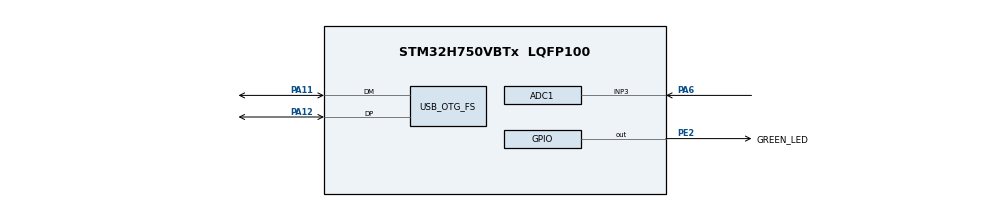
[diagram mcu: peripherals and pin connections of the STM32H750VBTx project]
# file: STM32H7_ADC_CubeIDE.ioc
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ADC1.Channel-0\#ChannelRegularConversion=ADC_CHANNEL_3
ADC1.ContinuousConvMode=DISABLE
ADC1.ConversionDataManagement=ADC_CONVERSIONDATA_DMA_CIRCULAR
ADC1.ExternalTrigConv=ADC_EXTERNALTRIG_T8_TRGO
ADC1.NbrOfConversion=1
ADC1.NbrOfConversionFlag=1
ADC1.OffsetNumber-0\#ChannelRegularConversion=ADC_OFFSET_NONE
ADC1.OffsetSignedSaturation-0\#ChannelRegularConversion=DISABLE
ADC1.OversamplingMode=ENABLE
ADC1.Rank-0\#ChannelRegularConversion=1
ADC1.Ratio=7
ADC1.RightBitShift=ADC_RIGHTBITSHIFT_3
ADC1.SamplingTime-0\#ChannelRegularConversion=ADC_SAMPLETIME_1CYCLE_5
ADC1.master=1
Dma.ADC1.0.Direction=DMA_PERIPH_TO_MEMORY
Dma.ADC1.0.EventEnable=DISABLE
Dma.ADC1.0.FIFOMode=DMA_FIFOMODE_DISABLE
Dma.ADC1.0.Instance=DMA1_Stream0
Dma.ADC1.0.MemDataAlignment=DMA_MDATAALIGN_HALFWORD
Dma.ADC1.0.MemInc=DMA_MINC_ENABLE
Dma.ADC1.0.Mode=DMA_CIRCULAR
Dma.ADC1.0.PeriphDataAlignment=DMA_PDATAALIGN_HALFWORD
Dma.ADC1.0.PeriphInc=DMA_PINC_DISABLE
Dma.ADC1.0.Polarity=HAL_DMAMUX_REQ_GEN_RISING
Dma.ADC1.0.Priority=DMA_PRIORITY_HIGH
Dma.ADC1.0.RequestNumber=1
Dma.ADC1.0.SignalID=NONE
Dma.ADC1.0.SyncEnable=DISABLE
Dma.ADC1.0.SyncPolarity=HAL_DMAMUX_SYNC_NO_EVENT
Dma.ADC1.0.SyncRequestNumber=1
Dma.ADC1.0.SyncSignalID=NONE
Dma.Request0=ADC1
Mcu.Family=STM32H7
Mcu.Name=STM32H750VBTx
Mcu.Package=LQFP100
NVIC.DMA1_Stream0_IRQn=true\:0\:0\:false\:false\:true\:false\:true\:true
NVIC.OTG_FS_IRQn=true\:0\:0\:false\:false\:true\:false\:true\:true
NVIC.PriorityGroup=NVIC_PRIORITYGROUP_4
PA11.Mode=Device_Only
PA11.Signal=USB_OTG_FS_DM
PA12.Mode=Device_Only
PA12.Signal=USB_OTG_FS_DP
PA13\ (JTMS/SWDIO).Mode=Serial_Wire
PA13\ (JTMS/SWDIO).Signal=DEBUG_JTMS-SWDIO
PA14\ (JTCK/SWCLK).Mode=Serial_Wire
PA14\ (JTCK/SWCLK).Signal=DEBUG_JTCK-SWCLK
PA6.Signal=ADCx_INP3
PC14-OSC32_IN\ (OSC32_IN).Mode=LSE-External-Oscillator
PC14-OSC32_IN\ (OSC32_IN).Signal=RCC_OSC32_IN
PC15-OSC32_OUT\ (OSC32_OUT).Mode=LSE-External-Oscillator
PC15-OSC32_OUT\ (OSC32_OUT).Signal=RCC_OSC32_OUT
PE2.GPIO_Label=GREEN_LED
PE2.Signal=GPIO_Output
PH0-OSC_IN\ (PH0).Mode=HSE-External-Oscillator
PH0-OSC_IN\ (PH0).Signal=RCC_OSC_IN
PH1-OSC_OUT\ (PH1).Mode=HSE-External-Oscillator
PH1-OSC_OUT\ (PH1).Signal=RCC_OSC_OUT
ProjectManager.HeapSize=0x400
ProjectManager.StackSize=0x800
ProjectManager.TargetToolchain=STM32CubeIDE
RCC.ADCFreq_Value=80000000
RCC.APB1Freq_Value=120000000
RCC.APB2Freq_Value=120000000
RCC.APB3Freq_Value=120000000
RCC.APB4Freq_Value=120000000
RCC.CortexFreq_Value=480000000
RCC.D1PPRE=RCC_APB3_DIV2
RCC.D2PPRE1=RCC_APB1_DIV2
RCC.D2PPRE2=RCC_APB2_DIV2
RCC.D3PPRE=RCC_APB4_DIV2
RCC.DIVM1=4
RCC.DIVM2=4
RCC.DIVN1=60
RCC.DIVN2=10
RCC.HCLKFreq_Value=240000000
RCC.HPRE=RCC_HCLK_DIV2
RCC.PLL2FRACN=0
RCC.PLL3FRACN=0
RCC.PLLFRACN=0
RCC.SYSCLKFreq_VALUE=480000000
RCC.SYSCLKSource=RCC_SYSCLKSOURCE_PLLCLK
RCC.USBCLockSelection=RCC_USBCLKSOURCE_HSI48
RCC.USBFreq_Value=48000000
SH.ADCx_INP3.0=ADC1_INP3,IN3-Single-Ended
TIM8.Period=2500-1
TIM8.Prescaler=2-1
TIM8.TIM_MasterOutputTrigger=TIM_TRGO_UPDATE
USB_DEVICE.CLASS_NAME_FS=CDC
USB_DEVICE.VirtualMode-CDC_FS=Cdc
USB_DEVICE.VirtualModeFS=Cdc_FS
USB_OTG_FS.VirtualMode=Device_Only
VP_MEMORYMAP_VS_MEMORYMAP.Mode=CurAppReg
VP_TIM8_VS_ClockSourceINT.Mode=Internal
VP_USB_DEVICE_VS_USB_DEVICE_CDC_FS.Mode=CDC_FS
board=custom

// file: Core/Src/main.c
/* USER CODE BEGIN Header */
/**
  ******************************************************************************
  * @file           : main.c
  * @brief          : Main program body
  ******************************************************************************
  * @attention
  *
  * Copyright (c) 2024 STMicroelectronics.
  * All rights reserved.
  *
  * This software is licensed under terms that can be found in the LICENSE file
  * in the root directory of this software component.
  * If no LICENSE file comes with this software, it is provided AS-IS.
  *
  ******************************************************************************
  */
/* USER CODE END Header */
#include "main.h"
#include "usb_device.h"

/* USER CODE BEGIN Includes */
#include "usbd_cdc_if.h"
/* USER CODE END Includes */

/* USER CODE BEGIN PD */
#define DMABUFLEN	2048
#define ADC_RAW_TO_VOLTAGE 0.00005035477f
/* USER CODE END PD */

ADC_HandleTypeDef hadc1;
DMA_HandleTypeDef hdma_adc1;

TIM_HandleTypeDef htim8;

/* USER CODE BEGIN PV */
volatile uint16_t dmaBuffer[DMABUFLEN];
volatile float potVoltage[DMABUFLEN];
volatile char msg[10];
/* USER CODE END PV */

void SystemClock_Config(void);
static void MX_GPIO_Init(void);
static void MX_DMA_Init(void);
static void MX_ADC1_Init(void);
static void MX_TIM8_Init(void);

/* USER CODE BEGIN 0 */

void HAL_ADC_ConvCpltCallback(ADC_HandleTypeDef *hadc){
	//HAL_GPIO_TogglePin(GREEN_LED_GPIO_Port, GREEN_LED_Pin);
	CDC_Transmit_FS((uint8_t*)&dmaBuffer[DMABUFLEN/2], DMABUFLEN);
//	HAL_ADC_Stop_DMA(&hadc1);
//	HAL_ADC_Start_DMA(&hadc1, (uint32_t*) dmaBuffer, DMABUFLEN);
}

void HAL_ADC_ConvHalfCpltCallback(ADC_HandleTypeDef *hadc){
	//HAL_GPIO_TogglePin(GREEN_LED_GPIO_Port, GREEN_LED_Pin);
	CDC_Transmit_FS((uint8_t*)&dmaBuffer[0], DMABUFLEN);
}
/* USER CODE END 0 */

int main(void)
{

  /* MCU Configuration--------------------------------------------------------*/

  /* Reset of all peripherals, Initializes the Flash interface and the Systick. */
  HAL_Init();

  /* Configure the system clock */
  SystemClock_Config();

  /* Initialize all configured peripherals */
  MX_GPIO_Init();
  MX_DMA_Init();
  MX_ADC1_Init();
  MX_TIM8_Init();
  MX_USB_DEVICE_Init();
  /* USER CODE BEGIN 2 */
  HAL_ADCEx_Calibration_Start(&hadc1, ADC_CALIB_OFFSET, ADC_SINGLE_ENDED);
  HAL_ADC_Start_DMA(&hadc1, (uint32_t*)dmaBuffer, DMABUFLEN);
  HAL_TIM_Base_Start(&htim8);
  /* USER CODE END 2 */

  /* Infinite loop */
  while (1)
  {

  }
}

void SystemClock_Config(void)
{
  RCC_OscInitTypeDef RCC_OscInitStruct = {0};
  RCC_ClkInitTypeDef RCC_ClkInitStruct = {0};

  /** Supply configuration update enable
  */
  HAL_PWREx_ConfigSupply(PWR_LDO_SUPPLY);

  /** Configure the main internal regulator output voltage
  */
  __HAL_PWR_VOLTAGESCALING_CONFIG(PWR_REGULATOR_VOLTAGE_SCALE1);

  while(!__HAL_PWR_GET_FLAG(PWR_FLAG_VOSRDY)) {}

  __HAL_RCC_SYSCFG_CLK_ENABLE();
  __HAL_PWR_VOLTAGESCALING_CONFIG(PWR_REGULATOR_VOLTAGE_SCALE0);

  while(!__HAL_PWR_GET_FLAG(PWR_FLAG_VOSRDY)) {}

  /** Initializes the RCC Oscillators according to the specified parameters
  * in the RCC_OscInitTypeDef structure.
  */
  RCC_OscInitStruct.OscillatorType = RCC_OSCILLATORTYPE_HSI48|RCC_OSCILLATORTYPE_HSI;
  RCC_OscInitStruct.HSIState = RCC_HSI_DIV1;
  RCC_OscInitStruct.HSICalibrationValue = RCC_HSICALIBRATION_DEFAULT;
  RCC_OscInitStruct.HSI48State = RCC_HSI48_ON;
  RCC_OscInitStruct.PLL.PLLState = RCC_PLL_ON;
  RCC_OscInitStruct.PLL.PLLSource = RCC_PLLSOURCE_HSI;
  RCC_OscInitStruct.PLL.PLLM = 4;
  RCC_OscInitStruct.PLL.PLLN = 60;
  RCC_OscInitStruct.PLL.PLLP = 2;
  RCC_OscInitStruct.PLL.PLLQ = 2;
  RCC_OscInitStruct.PLL.PLLR = 2;
  RCC_OscInitStruct.PLL.PLLRGE = RCC_PLL1VCIRANGE_3;
  RCC_OscInitStruct.PLL.PLLVCOSEL = RCC_PLL1VCOWIDE;
  RCC_OscInitStruct.PLL.PLLFRACN = 0;
  if (HAL_RCC_OscConfig(&RCC_OscInitStruct) != HAL_OK)
  {
    Error_Handler();
  }

  /** Initializes the CPU, AHB and APB buses clocks
  */
  RCC_ClkInitStruct.ClockType = RCC_CLOCKTYPE_HCLK|RCC_CLOCKTYPE_SYSCLK
                              |RCC_CLOCKTYPE_PCLK1|RCC_CLOCKTYPE_PCLK2
                              |RCC_CLOCKTYPE_D3PCLK1|RCC_CLOCKTYPE_D1PCLK1;
  RCC_ClkInitStruct.SYSCLKSource = RCC_SYSCLKSOURCE_PLLCLK;
  RCC_ClkInitStruct.SYSCLKDivider = RCC_SYSCLK_DIV1;
  RCC_ClkInitStruct.AHBCLKDivider = RCC_HCLK_DIV2;
  RCC_ClkInitStruct.APB3CLKDivider = RCC_APB3_DIV2;
  RCC_ClkInitStruct.APB1CLKDivider = RCC_APB1_DIV2;
  RCC_ClkInitStruct.APB2CLKDivider = RCC_APB2_DIV2;
  RCC_ClkInitStruct.APB4CLKDivider = RCC_APB4_DIV2;

  if (HAL_RCC_ClockConfig(&RCC_ClkInitStruct, FLASH_LATENCY_4) != HAL_OK)
  {
    Error_Handler();
  }
}

static void MX_ADC1_Init(void)
{

  ADC_MultiModeTypeDef multimode = {0};
  ADC_ChannelConfTypeDef sConfig = {0};

  /** Common config
  */
  hadc1.Instance = ADC1;
  hadc1.Init.ScanConvMode = ADC_SCAN_DISABLE;
  hadc1.Init.EOCSelection = ADC_EOC_SINGLE_CONV;
  hadc1.Init.LowPowerAutoWait = DISABLE;
  hadc1.Init.ContinuousConvMode = DISABLE;
  hadc1.Init.NbrOfConversion = 1;
  hadc1.Init.DiscontinuousConvMode = DISABLE;
  hadc1.Init.ExternalTrigConv = ADC_EXTERNALTRIG_T8_TRGO;
  hadc1.Init.ExternalTrigConvEdge = ADC_EXTERNALTRIGCONVEDGE_RISING;
  hadc1.Init.ConversionDataManagement = ADC_CONVERSIONDATA_DMA_CIRCULAR;
  hadc1.Init.Overrun = ADC_OVR_DATA_PRESERVED;
  hadc1.Init.LeftBitShift = ADC_LEFTBITSHIFT_NONE;
  hadc1.Init.OversamplingMode = ENABLE;
  hadc1.Init.Oversampling.Ratio = 7;
  hadc1.Init.Oversampling.RightBitShift = ADC_RIGHTBITSHIFT_3;
  hadc1.Init.Oversampling.TriggeredMode = ADC_TRIGGEREDMODE_SINGLE_TRIGGER;
  hadc1.Init.Oversampling.OversamplingStopReset = ADC_REGOVERSAMPLING_CONTINUED_MODE;
  if (HAL_ADC_Init(&hadc1) != HAL_OK)
  {
    Error_Handler();
  }
  hadc1.Init.ClockPrescaler = ADC_CLOCK_ASYNC_DIV1;
  hadc1.Init.Resolution = ADC_RESOLUTION_16B;
  if (HAL_ADC_Init(&hadc1) != HAL_OK)
  {
    Error_Handler();
  }

  /** Configure the ADC multi-mode
  */
  multimode.Mode = ADC_MODE_INDEPENDENT;
  if (HAL_ADCEx_MultiModeConfigChannel(&hadc1, &multimode) != HAL_OK)
  {
    Error_Handler();
  }

  /** Configure Regular Channel
  */
  sConfig.Channel = ADC_CHANNEL_3;
  sConfig.Rank = ADC_REGULAR_RANK_1;
  sConfig.SamplingTime = ADC_SAMPLETIME_1CYCLE_5;
  sConfig.SingleDiff = ADC_SINGLE_ENDED;
  sConfig.OffsetNumber = ADC_OFFSET_NONE;
  sConfig.Offset = 0;
  sConfig.OffsetSignedSaturation = DISABLE;
  if (HAL_ADC_ConfigChannel(&hadc1, &sConfig) != HAL_OK)
  {
    Error_Handler();
  }

}

static void MX_TIM8_Init(void)
{

  TIM_ClockConfigTypeDef sClockSourceConfig = {0};
  TIM_MasterConfigTypeDef sMasterConfig = {0};

  htim8.Instance = TIM8;
  htim8.Init.Prescaler = 2-1;
  htim8.Init.CounterMode = TIM_COUNTERMODE_UP;
  htim8.Init.Period = 2500-1;
  htim8.Init.ClockDivision = TIM_CLOCKDIVISION_DIV1;
  htim8.Init.RepetitionCounter = 0;
  htim8.Init.AutoReloadPreload = TIM_AUTORELOAD_PRELOAD_DISABLE;
  if (HAL_TIM_Base_Init(&htim8) != HAL_OK)
  {
    Error_Handler();
  }
  sClockSourceConfig.ClockSource = TIM_CLOCKSOURCE_INTERNAL;
  if (HAL_TIM_ConfigClockSource(&htim8, &sClockSourceConfig) != HAL_OK)
  {
    Error_Handler();
  }
  sMasterConfig.MasterOutputTrigger = TIM_TRGO_UPDATE;
  sMasterConfig.MasterOutputTrigger2 = TIM_TRGO2_RESET;
  sMasterConfig.MasterSlaveMode = TIM_MASTERSLAVEMODE_DISABLE;
  if (HAL_TIMEx_MasterConfigSynchronization(&htim8, &sMasterConfig) != HAL_OK)
  {
    Error_Handler();
  }

}

static void MX_DMA_Init(void)
{

  /* DMA controller clock enable */
  __HAL_RCC_DMA1_CLK_ENABLE();

  /* DMA interrupt init */
  /* DMA1_Stream0_IRQn interrupt configuration */
  HAL_NVIC_SetPriority(DMA1_Stream0_IRQn, 0, 0);
  HAL_NVIC_EnableIRQ(DMA1_Stream0_IRQn);

}

static void MX_GPIO_Init(void)
{
  GPIO_InitTypeDef GPIO_InitStruct = {0};

  /* GPIO Ports Clock Enable */
  __HAL_RCC_GPIOE_CLK_ENABLE();
  __HAL_RCC_GPIOC_CLK_ENABLE();
  __HAL_RCC_GPIOH_CLK_ENABLE();
  __HAL_RCC_GPIOA_CLK_ENABLE();

  /*Configure GPIO pin Output Level */
  HAL_GPIO_WritePin(GREEN_LED_GPIO_Port, GREEN_LED_Pin, GPIO_PIN_RESET);

  /*Configure GPIO pin : GREEN_LED_Pin */
  GPIO_InitStruct.Pin = GREEN_LED_Pin;
  GPIO_InitStruct.Mode = GPIO_MODE_OUTPUT_PP;
  GPIO_InitStruct.Pull = GPIO_NOPULL;
  GPIO_InitStruct.Speed = GPIO_SPEED_FREQ_LOW;
  HAL_GPIO_Init(GREEN_LED_GPIO_Port, &GPIO_InitStruct);

}

void Error_Handler(void)
{
  __disable_irq();
  while (1)
  {
  }
}
